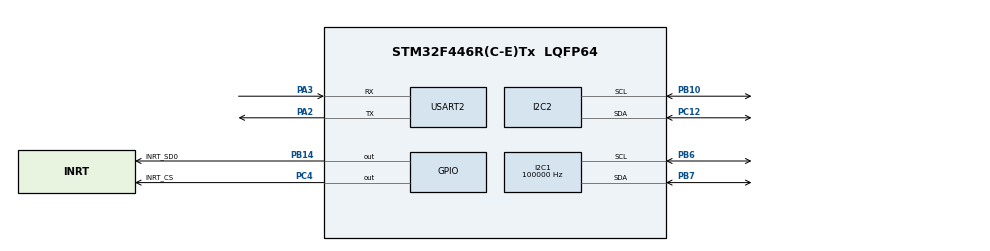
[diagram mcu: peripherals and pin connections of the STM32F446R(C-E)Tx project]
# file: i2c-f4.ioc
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I2C1.ClockSpeed=100000
Mcu.Family=STM32F4
Mcu.Name=STM32F446R(C-E)Tx
Mcu.Package=LQFP64
NVIC.I2C1_EV_IRQn=true\:0\:0\:false\:false\:true\:true
NVIC.I2C2_EV_IRQn=true\:0\:0\:false\:false\:true\:true
NVIC.PriorityGroup=NVIC_PRIORITYGROUP_4
PA2.Mode=Asynchronous
PA2.Signal=USART2_TX
PA3.Mode=Asynchronous
PA3.Signal=USART2_RX
PB10.Mode=I2C
PB10.Signal=I2C2_SCL
PB14.GPIO_Label=INRT_SD0
PB14.Signal=GPIO_Output
PB6.Mode=I2C
PB6.Signal=I2C1_SCL
PB7.Mode=I2C
PB7.Signal=I2C1_SDA
PC12.Mode=I2C
PC12.Signal=I2C2_SDA
PC4.GPIO_Label=INRT_CS
PC4.Signal=GPIO_Output
ProjectManager.HeapSize=0x200
ProjectManager.StackSize=0x400
ProjectManager.TargetToolchain=TrueSTUDIO
RCC.CortexFreq_Value=16000000
RCC.USBFreq_Value=96000000
RCC.VCOOutputFreq_Value=192000000
USART2.VirtualMode=VM_ASYNC
board=custom

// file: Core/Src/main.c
/**
  ******************************************************************************
  * @file           : main.c
  * @brief          : Main program body
  ******************************************************************************
  ** This notice applies to any and all portions of this file
  * that are not between comment pairs USER CODE BEGIN and
  * USER CODE END. Other portions of this file, whether
  * inserted by the user or by software development tools
  * are owned by their respective copyright owners.
  *
  * COPYRIGHT(c) 2018 STMicroelectronics
  *
  * Redistribution and use in source and binary forms, with or without modification,
  * are permitted provided that the following conditions are met:
  *   1. Redistributions of source code must retain the above copyright notice,
  *      this list of conditions and the following disclaimer.
  *   2. Redistributions in binary form must reproduce the above copyright notice,
  *      this list of conditions and the following disclaimer in the documentation
  *      and/or other materials provided with the distribution.
  *   3. Neither the name of STMicroelectronics nor the names of its contributors
  *      may be used to endorse or promote products derived from this software
  *      without specific prior written permission.
  *
  * THIS SOFTWARE IS PROVIDED BY THE COPYRIGHT HOLDERS AND CONTRIBUTORS "AS IS"
  * AND ANY EXPRESS OR IMPLIED WARRANTIES, INCLUDING, BUT NOT LIMITED TO, THE
  * IMPLIED WARRANTIES OF MERCHANTABILITY AND FITNESS FOR A PARTICULAR PURPOSE ARE
  * DISCLAIMED. IN NO EVENT SHALL THE COPYRIGHT HOLDER OR CONTRIBUTORS BE LIABLE
  * FOR ANY DIRECT, INDIRECT, INCIDENTAL, SPECIAL, EXEMPLARY, OR CONSEQUENTIAL
  * DAMAGES (INCLUDING, BUT NOT LIMITED TO, PROCUREMENT OF SUBSTITUTE GOODS OR
  * SERVICES; LOSS OF USE, DATA, OR PROFITS; OR BUSINESS INTERRUPTION) HOWEVER
  * CAUSED AND ON ANY THEORY OF LIABILITY, WHETHER IN CONTRACT, STRICT LIABILITY,
  * OR TORT (INCLUDING NEGLIGENCE OR OTHERWISE) ARISING IN ANY WAY OUT OF THE USE
  * OF THIS SOFTWARE, EVEN IF ADVISED OF THE POSSIBILITY OF SUCH DAMAGE.
  *
  ******************************************************************************
  */
#include "main.h"
#include "stm32f4xx_hal.h"
#include "i2c.h"
#include "usart.h"
#include "gpio.h"

/* USER CODE BEGIN Includes */
#include "inrt.h"
#include "string.h"
/* USER CODE END Includes */

/* USER CODE BEGIN PV */
/* Private variables ---------------------------------------------------------*/

/* USER CODE END PV */

void SystemClock_Config(void);

/* USER CODE BEGIN PFP */
/* Private function prototypes -----------------------------------------------*/

/* USER CODE END PFP */

/* USER CODE BEGIN 0 */

void HAL_I2C_MasterRxCpltCallback(I2C_HandleTypeDef *hi2c)
{

}

/* USER CODE END 0 */

int main(void)
{

  /* MCU Configuration----------------------------------------------------------*/

  /* Reset of all peripherals, Initializes the Flash interface and the Systick. */
  HAL_Init();

  /* Configure the system clock */
  SystemClock_Config();

  /* Initialize all configured peripherals */
  MX_GPIO_Init();
  MX_I2C1_Init();
  MX_I2C2_Init();
  MX_USART2_UART_Init();
  /* USER CODE BEGIN 2 */

  Inertia inrt;
  InitInertia();

  /* USER CODE END 2 */

  /* Infinite loop */
  /* USER CODE BEGIN WHILE */
  char buf[60];

  while (1)
  {
	  inrt = GetInertia();

	  sprintf(buf, "a_x = %d mm/s^2\na_y = %d mm/s^2\na_z = %d mm/s^2\n\n", inrt.a_x, inrt.a_y, inrt.a_z);
	  HAL_UART_Transmit(&huart2, buf, strlen(buf), HAL_MAX_DELAY);

	  HAL_Delay(5000);
  /* USER CODE END WHILE */

  /* USER CODE BEGIN 3 */
  }

  /* Ezeket a callbackeket kИne hasznАlnunk
   *
   * void HAL_I2C_EV_IRQHandler(I2C_HandleTypeDef *hi2c);
void HAL_I2C_ER_IRQHandler(I2C_HandleTypeDef *hi2c);
void HAL_I2C_MasterTxCpltCallback(I2C_HandleTypeDef *hi2c);
void HAL_I2C_MasterRxCpltCallback(I2C_HandleTypeDef *hi2c);
void HAL_I2C_SlaveTxCpltCallback(I2C_HandleTypeDef *hi2c);
void HAL_I2C_SlaveRxCpltCallback(I2C_HandleTypeDef *hi2c);
void HAL_I2C_AddrCallback(I2C_HandleTypeDef *hi2c, uint8_t TransferDirection, uint16_t AddrMatchCode);
void HAL_I2C_ListenCpltCallback(I2C_HandleTypeDef *hi2c);
void HAL_I2C_MemTxCpltCallback(I2C_HandleTypeDef *hi2c);
void HAL_I2C_MemRxCpltCallback(I2C_HandleTypeDef *hi2c);
void HAL_I2C_ErrorCallback(I2C_HandleTypeDef *hi2c);
void HAL_I2C_AbortCpltCallback(I2C_HandleTypeDef *hi2c);
   */

  /* USER CODE END 3 */

}

void SystemClock_Config(void)
{

  RCC_OscInitTypeDef RCC_OscInitStruct;
  RCC_ClkInitTypeDef RCC_ClkInitStruct;

    /**Configure the main internal regulator output voltage
    */
  __HAL_RCC_PWR_CLK_ENABLE();

  __HAL_PWR_VOLTAGESCALING_CONFIG(PWR_REGULATOR_VOLTAGE_SCALE3);

    /**Initializes the CPU, AHB and APB busses clocks
    */
  RCC_OscInitStruct.OscillatorType = RCC_OSCILLATORTYPE_HSI;
  RCC_OscInitStruct.HSIState = RCC_HSI_ON;
  RCC_OscInitStruct.HSICalibrationValue = 16;
  RCC_OscInitStruct.PLL.PLLState = RCC_PLL_NONE;
  if (HAL_RCC_OscConfig(&RCC_OscInitStruct) != HAL_OK)
  {
    _Error_Handler(__FILE__, __LINE__);
  }

    /**Initializes the CPU, AHB and APB busses clocks
    */
  RCC_ClkInitStruct.ClockType = RCC_CLOCKTYPE_HCLK|RCC_CLOCKTYPE_SYSCLK
                              |RCC_CLOCKTYPE_PCLK1|RCC_CLOCKTYPE_PCLK2;
  RCC_ClkInitStruct.SYSCLKSource = RCC_SYSCLKSOURCE_HSI;
  RCC_ClkInitStruct.AHBCLKDivider = RCC_SYSCLK_DIV1;
  RCC_ClkInitStruct.APB1CLKDivider = RCC_HCLK_DIV1;
  RCC_ClkInitStruct.APB2CLKDivider = RCC_HCLK_DIV1;

  if (HAL_RCC_ClockConfig(&RCC_ClkInitStruct, FLASH_LATENCY_0) != HAL_OK)
  {
    _Error_Handler(__FILE__, __LINE__);
  }

    /**Configure the Systick interrupt time
    */
  HAL_SYSTICK_Config(HAL_RCC_GetHCLKFreq()/1000);

    /**Configure the Systick
    */
  HAL_SYSTICK_CLKSourceConfig(SYSTICK_CLKSOURCE_HCLK);

  /* SysTick_IRQn interrupt configuration */
  HAL_NVIC_SetPriority(SysTick_IRQn, 0, 0);
}

void _Error_Handler(char *file, int line)
{
  while(1)
  {
  }
}

/************************ (C) COPYRIGHT STMicroelectronics *****END OF FILE****/
